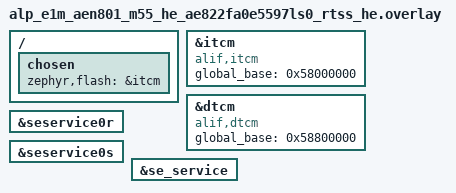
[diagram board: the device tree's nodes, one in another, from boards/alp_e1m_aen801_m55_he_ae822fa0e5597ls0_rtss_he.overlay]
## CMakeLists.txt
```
# SPDX-License-Identifier: Apache-2.0
#
# aen-dualcore-he-master -- the HE-master -> HP-peer direction of B1 Option B,
# self-contained (unlike aen-dualcore-master, which is symmetric and needs the
# separate aen-dualcore-probe app hand-paired in as the HP peer). Built TWICE:
# the HE board target is the master role (src/main.c calls
# alp_mproc_boot_core(ALP_CORE_M55_HP, ...) via the deferred-TOC path -- see
# README.md for why this direction can't use the plain 501 release path); the
# HP board target is the peer role (a passive SRAM0 beacon, like
# aen-dualcore-probe). One source file, role picked by CONFIG_SOC_*_RTSS_HP
# (a SoC-core fact, true on either SKU) at compile time, same pattern as
# every other aen-dualcore-* example.
cmake_minimum_required(VERSION 3.20)
find_package(Zephyr REQUIRED HINTS $ENV{ZEPHYR_BASE})
project(aen_dualcore_he_master LANGUAGES C)
target_sources(app PRIVATE src/main.c)
```

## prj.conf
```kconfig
# SPDX-License-Identifier: Apache-2.0
#
# Bench RAM-run config, shared by both the HE (master) and HP (peer) builds.
# Role-specific Kconfig (the SE boot backend, the deferred-TOC selection) lives
# in boards/<he-target>.conf -- Zephyr auto-merges a boards/<fully-qualified
# board>.conf into this file, HP gets none of it and stays a lean beacon-only
# image, same split aen-dualcore-doorbell/aen-dualcore-ipc use elsewhere.
#
# Like every other aen-dualcore-* example: both M55 cores are read through one
# SWD buffer (master-agnostic), and a single UART5 can't serve both cores, so
# this stays on the RAM console rather than the newer Alp-UART default.
CONFIG_RAM_CONSOLE=y
CONFIG_RAM_CONSOLE_BUFFER_SIZE=2048
CONFIG_UART_CONSOLE=n
CONFIG_CONSOLE=y
CONFIG_PRINTK=y

# Keep the image small + deterministic for a RAM-run. LOG MUST stay off --
# CONFIG_LOG=y reroutes printk into the logging subsystem, which has no
# RAM-console backend, so the RESULT line never reaches 'ram_console_buf'.
CONFIG_LOG=n

# Non-negotiable for this app, both boards: (1) the E8 D-cache maintenance
# loop hangs on this silicon (shared bench rule -- see aen-hp-core-smoke,
# aen-gpu2d-bench); (2) the two beacons this app polls (its own + the peer's)
# live in cross-core global SRAM0, which is NOT coherent between the M55-HE
# and M55-HP D-caches -- a cached read can sit on a stale line forever while
# the other core's write already landed, i.e. an all-else-correct build
# reports RESULT SKIP against a peer that is, in fact, up and heartbeating
# (PR #1080's finding on three sibling dual-core examples that omitted
# this). A cache-on variant would need sys_cache_data_flush_range on every
# beacon write + sys_cache_data_invd_range before every cross-core beacon
# read.
CONFIG_DCACHE=n
```

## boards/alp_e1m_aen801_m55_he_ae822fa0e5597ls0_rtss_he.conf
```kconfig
#
# E1M-AEN801 / Alif Ensemble E8: the MASTER role. HE is the SES-booted core
# here (ATOC entry ["load","boot"] @0x58000000); it releases the HP peer at
# runtime over the Secure Enclave boot service.
#
# Tier-2 driver Kconfigs (incl. CONFIG_ARM_MHUV2 / CONFIG_HAS_ALIF_SE_SERVICES)
# are gated under ALP_SDK.
CONFIG_ALP_SDK=y

# SE service transport. CONFIG_ARM_MHUV2 builds the in-tree "arm,mhuv2" IPM
# driver; CONFIG_HAS_ALIF_SE_SERVICES compiles the hal_alif SE client the
# SDK's boot backend consumes -- this app itself calls only the portable
# alp_mproc_boot_core() (<alp/mproc.h>).  Both default y under the relevant
# DT_HAS_*_ENABLED (boards/<this-file-minus-.conf>.overlay okays the SE
# mailbox nodes), set explicitly so the build is self-describing.
CONFIG_ARM_MHUV2=y
CONFIG_HAS_ALIF_SE_SERVICES=y

# The load-bearing selection: this build's peer is M55-HP, not M55-HE.
# Setting only THIS symbol is deliberate -- everything else cascades from its
# Kconfig defaults (zephyr/kconfigs/mproc-rpc-usb.kconfig):
#   - CONFIG_ALP_SDK_MPROC_BOOT_ALIF_SE_DEFERRED_TOC defaults to y once the
#     peer is HP (the plain service-501 release path is vendor-documented
#     broken for an HP peer -- see README.md and
#     src/backends/mproc/alif_se_boot.c); it stays n for an HE peer, where
#     501 is bench-proven fine and flipping the default would break every
#     existing HE-peer ATOC.
#   - CONFIG_ALP_SDK_MPROC_BOOT_ALIF_SE_DEFERRED_TOC_ENTRY_ID defaults to
#     "ALP-HP" once the peer is HP -- the ATOC entry key
#     se_service_process_toc_entry() un-defers at runtime (see README.md's
#     ATOC shape: this string MUST match the flashed entry's JSON key
#     exactly, or the un-defer request silently targets nothing).
# Hardcoding either of those here instead would fight the single-source
# Kconfig default and drift if the defaults ever change.
CONFIG_ALP_SDK_MPROC_BOOT_ALIF_SE_DEFERRED_TOC_PEER_IS_HP=y
```

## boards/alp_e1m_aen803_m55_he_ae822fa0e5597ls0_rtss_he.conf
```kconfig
#
# E1M-AEN803 / Alif Ensemble E8: the MASTER role. HE is the SES-booted core
# here (ATOC entry ["load","boot"] @0x58000000); it releases the HP peer at
# runtime over the Secure Enclave boot service.
#
# Tier-2 driver Kconfigs (incl. CONFIG_ARM_MHUV2 / CONFIG_HAS_ALIF_SE_SERVICES)
# are gated under ALP_SDK.
CONFIG_ALP_SDK=y

# SE service transport. CONFIG_ARM_MHUV2 builds the in-tree "arm,mhuv2" IPM
# driver; CONFIG_HAS_ALIF_SE_SERVICES compiles the hal_alif SE client the
# SDK's boot backend consumes -- this app itself calls only the portable
# alp_mproc_boot_core() (<alp/mproc.h>).  Both default y under the relevant
# DT_HAS_*_ENABLED (boards/<this-file-minus-.conf>.overlay okays the SE
# mailbox nodes), set explicitly so the build is self-describing.
CONFIG_ARM_MHUV2=y
CONFIG_HAS_ALIF_SE_SERVICES=y

# The load-bearing selection: this build's peer is M55-HP, not M55-HE.
# Setting only THIS symbol is deliberate -- everything else cascades from its
# Kconfig defaults (zephyr/kconfigs/mproc-rpc-usb.kconfig):
#   - CONFIG_ALP_SDK_MPROC_BOOT_ALIF_SE_DEFERRED_TOC defaults to y once the
#     peer is HP (the plain service-501 release path is vendor-documented
#     broken for an HP peer -- see README.md and
#     src/backends/mproc/alif_se_boot.c); it stays n for an HE peer, where
#     501 is bench-proven fine and flipping the default would break every
#     existing HE-peer ATOC.
#   - CONFIG_ALP_SDK_MPROC_BOOT_ALIF_SE_DEFERRED_TOC_ENTRY_ID defaults to
#     "ALP-HP" once the peer is HP -- the ATOC entry key
#     se_service_process_toc_entry() un-defers at runtime (see README.md's
#     ATOC shape: this string MUST match the flashed entry's JSON key
#     exactly, or the un-defer request silently targets nothing).
# Hardcoding either of those here instead would fight the single-source
# Kconfig default and drift if the defaults ever change.
CONFIG_ALP_SDK_MPROC_BOOT_ALIF_SE_DEFERRED_TOC_PEER_IS_HP=y
```

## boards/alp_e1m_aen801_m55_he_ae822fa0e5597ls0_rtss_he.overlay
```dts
/*
 * Copyright (c) 2026 Alp Lab AB
 * SPDX-License-Identifier: Apache-2.0
 *
 * aen-dualcore-he-master overlay for the E1M-AEN801 (Ensemble E8, M55-HE)
 * MASTER role RAM-run.
 *
 * The SE SERVICE transport nodes live in the E8 SoC overlay
 * (zephyr/dts/alif/ensemble_e8_peripherals.dtsi) status="disabled" by default
 * (they are SoC-fixed: the RTSS-HE <-> SE MHUv2 mailbox pair + the se_service
 * root node). This overlay enables them for the RTSS-HE core:
 *   - seservice0r (arm,mhuv2 @ 0x40040000, IRQ 37, "rx") -- SE -> RTSS inbound
 *   - seservice0s (arm,mhuv2 @ 0x40050000, IRQ 38, "tx") -- RTSS -> SE outbound
 *   - se_service  (alif,secure-enclave-services) -- ties the two via phandles
 * No clocks / pinctrl: the MHUv2 mailboxes are core-internal (no pads, no
 * peripheral clock gate); the driver only maps MMIO + wires the IRQ.
 */

/*
 * RAM-run: retarget ROM to ITCM (path-reference form &itcm; the phandle-array
 * form makes FLASH_SIZE=0 and overflows the link) -- the aen-adc-regcheck
 * precedent, same as every other aen-dualcore-* example.
 */
/ {
	chosen {
		zephyr,flash = &itcm;
		/delete-property/ zephyr,code-partition;
	};
};

/*
 * itcm/dtcm `global_base` for local_to_global() -- hal_alif se_service.c puts
 * its outbound SE message buffer through local_to_global() (soc_memory_map.h),
 * which reads DT_PROP(itcm/dtcm, global_base) to translate the M55-local
 * address into the global view the SE's DMA sees. Upstream Zephyr's
 * arm,itcm/arm,dtcm bindings have no such prop, so re-`compatible` the nodes
 * onto the alp-sdk alif,itcm/alif,dtcm bindings (which declare global_base)
 * and set the E8 RTSS-HE global TCM aliases (ITCM 0x58000000, DTCM
 * 0x58800000), the same values every other SE-service-using aen-dualcore-*
 * HE build sets. The HP peer role in this same example needs none of this --
 * it never calls into se_service.c, so its overlay skips both the SE nodes
 * and this re-`compatible`.
 */
&itcm {
	compatible = "alif,itcm";
	global_base = <0x58000000>;
};

&dtcm {
	compatible = "alif,dtcm";
	global_base = <0x58800000>;
};

&seservice0r {
	status = "okay";
};

&seservice0s {
	status = "okay";
};

&se_service {
	status = "okay";
};
```

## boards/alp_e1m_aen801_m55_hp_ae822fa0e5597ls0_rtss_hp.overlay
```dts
/*
 * Copyright (c) 2026 Alp Lab AB
 * SPDX-License-Identifier: Apache-2.0
 *
 * aen-dualcore-he-master overlay for the E1M-AEN801 (Ensemble E8, M55-HP)
 * PEER role RAM-run.
 *
 * The peer role never calls alp_mproc_boot_core() or any other SE service --
 * it only stamps a beacon in global SRAM0 (see src/main.c) -- so unlike the HE
 * master's overlay, no SE mailbox nodes and no itcm/dtcm global_base
 * re-`compatible` are needed here (local_to_global() is never reached on this
 * side). Just the ITCM link retarget, the same one aen-dualcore-probe uses for
 * both boards via a single app.overlay.
 */
/ {
	chosen {
		zephyr,flash = &itcm;
		/delete-property/ zephyr,code-partition;
	};
};
```

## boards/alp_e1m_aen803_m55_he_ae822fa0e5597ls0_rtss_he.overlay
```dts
/*
 * Copyright (c) 2026 Alp Lab AB
 * SPDX-License-Identifier: Apache-2.0
 *
 * aen-dualcore-he-master overlay for the E1M-AEN803 (Ensemble E8, M55-HE)
 * MASTER role RAM-run.
 *
 * The SE SERVICE transport nodes live in the E8 SoC overlay
 * (zephyr/dts/alif/ensemble_e8_peripherals.dtsi) status="disabled" by default
 * (they are SoC-fixed: the RTSS-HE <-> SE MHUv2 mailbox pair + the se_service
 * root node). This overlay enables them for the RTSS-HE core:
 *   - seservice0r (arm,mhuv2 @ 0x40040000, IRQ 37, "rx") -- SE -> RTSS inbound
 *   - seservice0s (arm,mhuv2 @ 0x40050000, IRQ 38, "tx") -- RTSS -> SE outbound
 *   - se_service  (alif,secure-enclave-services) -- ties the two via phandles
 * No clocks / pinctrl: the MHUv2 mailboxes are core-internal (no pads, no
 * peripheral clock gate); the driver only maps MMIO + wires the IRQ.
 */

/*
 * RAM-run: retarget ROM to ITCM (path-reference form &itcm; the phandle-array
 * form makes FLASH_SIZE=0 and overflows the link) -- the aen-adc-regcheck
 * precedent, same as every other aen-dualcore-* example.
 */
/ {
	chosen {
		zephyr,flash = &itcm;
		/delete-property/ zephyr,code-partition;
	};
};

/*
 * itcm/dtcm `global_base` for local_to_global() -- hal_alif se_service.c puts
 * its outbound SE message buffer through local_to_global() (soc_memory_map.h),
 * which reads DT_PROP(itcm/dtcm, global_base) to translate the M55-local
 * address into the global view the SE's DMA sees. Upstream Zephyr's
 * arm,itcm/arm,dtcm bindings have no such prop, so re-`compatible` the nodes
 * onto the alp-sdk alif,itcm/alif,dtcm bindings (which declare global_base)
 * and set the E8 RTSS-HE global TCM aliases (ITCM 0x58000000, DTCM
 * 0x58800000), the same values every other SE-service-using aen-dualcore-*
 * HE build sets. The HP peer role in this same example needs none of this --
 * it never calls into se_service.c, so its overlay skips both the SE nodes
 * and this re-`compatible`.
 */
&itcm {
	compatible = "alif,itcm";
	global_base = <0x58000000>;
};

&dtcm {
	compatible = "alif,dtcm";
	global_base = <0x58800000>;
};

&seservice0r {
	status = "okay";
};

&seservice0s {
	status = "okay";
};

&se_service {
	status = "okay";
};
```

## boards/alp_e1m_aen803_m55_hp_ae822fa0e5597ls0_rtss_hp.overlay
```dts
/*
 * Copyright (c) 2026 Alp Lab AB
 * SPDX-License-Identifier: Apache-2.0
 *
 * aen-dualcore-he-master overlay for the E1M-AEN803 (Ensemble E8, M55-HP)
 * PEER role RAM-run.
 *
 * The peer role never calls alp_mproc_boot_core() or any other SE service --
 * it only stamps a beacon in global SRAM0 (see src/main.c) -- so unlike the HE
 * master's overlay, no SE mailbox nodes and no itcm/dtcm global_base
 * re-`compatible` are needed here (local_to_global() is never reached on this
 * side). Just the ITCM link retarget, the same one aen-dualcore-probe uses for
 * both boards via a single app.overlay.
 */
/ {
	chosen {
		zephyr,flash = &itcm;
		/delete-property/ zephyr,code-partition;
	};
};
```

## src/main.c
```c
/*
 * Copyright (c) 2026 Alp Lab AB
 * SPDX-License-Identifier: Apache-2.0
 *
 * aen-dualcore-he-master -- the HE-master -> HP-peer direction of B1 Option B
 * (portable alp_mproc_boot_core(), <alp/mproc.h>), as its OWN example instead
 * of a hand-paired combination of two others.
 *
 * Every other AEN dual-core example that releases a peer (aen-dualcore-master,
 * aen-dualcore-doorbell, aen-dualcore-ipc, ...) releases it HP-master ->
 * HE-peer. That direction works with the plain se_service_boot_cpu() release
 * path (service 501). This example is the OTHER direction -- HE releases HP
 * -- which 501 cannot do at all: Alif's SE Host Services API docs
 * (SE_Host_Services_API_v1.109.0.pdf) say plainly that 501 "does not perform
 * image loading, verification, etc., it just boots the core" (p.112), and
 * that resetting the M55-HP core specifically invalidates its TCM content
 * on release -- p.112 scopes this to "FUSION REV_Bx devices", p.115 instead
 * says "Ensemble devices" with no qualifier
 * (E8 is Ensemble, so p.115 covers it either way; the two vendor passages
 * disagree with each other on scope and are cited here rather than
 * resolved). Bench-measured on E8 (2026-07-31, HE master releasing an HP
 * peer via 501): the SES table reported HP Loaded/Verified, but its ITCM
 * read as uninitialized SRAM, and releasing it vectored the core from empty
 * memory -- CFSR=0x00000101 (IACCVIOL+IBUSERR), PC=0xEFFFFFFE.
 *
 * The fix is service 500 (se_service_process_toc_entry(), "a convenient way
 * to boot a CPU core", p.112) against a peer ATOC entry flagged
 * ["load","boot","deferred"]: the SES skips the entry entirely at power-on
 * (SETOOLS guide AUGD0005 v1.110.0 p.35: "skipped at boot time, i.e., no boot OR
 * load"), and this master's boot_core() call un-defers it at runtime -- load,
 * verify AND release together, strictly AFTER whatever reset the release
 * involves, matching p.115's own documented remedy (reset -> reload ->
 * release). This build selects that path via
 * CONFIG_ALP_SDK_MPROC_BOOT_ALIF_SE_DEFERRED_TOC_PEER_IS_HP=y
 * (boards/alp_e1m_aen801_m55_he_ae822fa0e5597ls0_rtss_he.conf), which
 * cascades CONFIG_ALP_SDK_MPROC_BOOT_ALIF_SE_DEFERRED_TOC=y and
 * CONFIG_..._ENTRY_ID="ALP-HP" from their own Kconfig defaults -- see
 * zephyr/kconfigs/mproc-rpc-usb.kconfig. Silicon-proven on E8, 2026-08-01,
 * as this exact self-contained example (a from-scratch bench rebuild
 * reproduced the authoring build's zephyr.bin md5s bit-exactly): see
 * README.md.
 *
 * ONE app, role-by-board, same pattern as every sibling:
 *   - built for the RTSS-HE board -> MASTER: SES-booted normally
 *     (["load","boot"] @0x58000000), calls alp_mproc_boot_core() to release
 *     the deferred HP peer.
 *   - built for the RTSS-HP board -> PEER: SES-DEFERRED (["load","boot",
 *     "deferred"] @0x50000000), never boots itself and never calls a boot
 *     API -- it only comes up when the master's runtime request un-defers
 *     it, then stamps a global-SRAM0 beacon like every other peer role in
 *     this family.
 *
 * alp_mproc_boot_core() returning ALP_OK only confirms the SE boot authority
 * ACCEPTED the un-defer request -- it says nothing about whether the peer
 * actually came up (that is the entire lesson this example exists to teach:
 * the plain-501 direction above is ALSO accepted with rc=ALP_OK and STILL
 * fails on real silicon). So this master polls the peer's own beacon for a
 * bounded window and only claims PASS once that word is observed to move --
 * never on the accepted return code alone.
 *
 * Message discipline: every non-PASS verdict below states what was
 * OBSERVED (the peer's beacon word did not advance within the bound), never
 * an inferred cause ("peer never ran") -- CONFIG_DCACHE=n exists specifically
 * because an inferred "peer never ran" was WRONG on this bench: the peer was
 * running and its beacon was genuinely advancing, just invisible to a cached
 * cross-core read (see prj.conf).
 *
 * Build (see README.md for the ATOC + flags this pairs with):
 *   west build -b alp_e1m_aen801_m55_he/ae822fa0e5597ls0/rtss_he \
 *     examples/aen/aen-dualcore-he-master -d build/he -- \
 *     "-DEXTRA_ZEPHYR_MODULES=<alp-sdk>;<hal_alif>"
 *   west build -b alp_e1m_aen801_m55_hp/ae822fa0e5597ls0/rtss_hp \
 *     examples/aen/aen-dualcore-he-master -d build/hp -- \
 *     "-DEXTRA_ZEPHYR_MODULES=<alp-sdk>;<hal_alif>"
 */

#include <stdbool.h>
#include <stdint.h>
#include <zephyr/kernel.h>
#include <zephyr/sys/printk.h>

/* <alp/mproc.h> is included further down, MASTER-role only: the PEER role
 * never calls into the SDK (it doesn't even build with CONFIG_ALP_SDK=y --
 * see prj.conf / boards/ *.conf), so its include path doesn't carry this
 * header at all. Keeping the include role-scoped, not just the call, keeps
 * the peer build exactly as lean as aen-dualcore-probe's. */

/* Global-SRAM0 beacon addresses + magics -- the same scheme (and the same
 * literal addresses) every aen-dualcore-* example uses, so a bench operator
 * reading this app over SWD needs no new mental model. 0x02000000 itself
 * reads back 0 even when running (reserved/special per the bench), so both
 * beacons sit at nonzero offsets. */
#define HP_BEACON ((volatile uint32_t *)0x02000010U) /* HP's own beacon slot */
#define HP_MAGIC  0xB1B10090U
#define HE_BEACON ((volatile uint32_t *)0x02001010U) /* HE's own beacon slot */
#define HE_BOOT   ((volatile uint32_t *)0x02001018U) /* HE-only: boot_core() rc */
#define HE_MAGIC  0xB1B100E0U
#define HP_ENTRY  0x50000000U /* HP ITCM global alias = the deferred ATOC entry's loadAddress */

/* Bounded wait for the peer's heartbeat to move at least once. Generous vs.
 * a cold M55 boot-to-main(): if the peer never advances within this window
 * on a bench where boot_core reported success, that IS the observation --
 * not proof of what the peer is doing, just that this core never saw it
 * move. */
#define PEER_HB_TIMEOUT_MS 2000U
#define PEER_HB_POLL_MS    20U

#if defined(CONFIG_SOC_AE822FA0E5597LS0_RTSS_HP)

/* PEER role: passive. This core's ATOC entry is ["load","boot","deferred"],
 * so it never runs until the HE master's boot_core() call un-defers it --
 * reaching main() at all is itself part of the proof the deferred-TOC
 * release worked. From here it behaves exactly like aen-dualcore-probe:
 * stamp a beacon, then heartbeat forever for the master (or a bench SWD
 * read) to observe.
 */
int main(void)
{
	printk("\n=== aen-dualcore-he-master (HP peer) beacon@0x02000010 ===\n");

	HP_BEACON[0] = HP_MAGIC;
	HP_BEACON[1] = 0U;

	for (uint32_t hb = 1U;; hb++) {
		HP_BEACON[1] = hb;
		if ((hb & 0x3FFU) == 0U) {
			printk("HP heartbeat %u\n", hb);
		}
		for (volatile uint32_t d = 0U; d < 200000U; d++) {
			/* crude delay so the heartbeat is human-observable */
		}
	}

	return 0;
}

#else

#include <alp/mproc.h>

/* MASTER role (default: any board that isn't the HP peer, i.e. RTSS-HE --
 * core-role selection, not a peripheral-presence gate, same convention as
 * every sibling example). */
int main(void)
{
	printk("\n=== aen-dualcore-he-master (HE master) -- release the deferred HP peer "
	       "via alp_mproc_boot_core ===\n");

	HE_BEACON[0] = HE_MAGIC;
	HE_BEACON[1] = 0U;

	alp_status_t rc = alp_mproc_boot_core(ALP_CORE_M55_HP, HP_ENTRY);

	HE_BOOT[0] = 0xB007C0DEU;
	HE_BOOT[1] = (uint32_t)rc;
	printk("alp_mproc_boot_core(M55-HP, 0x%08x) rc=%d\n", HP_ENTRY, (int)rc);

	if (rc != ALP_OK) {
		/* State only the observation: boot_core() itself returned a
		 * nonzero rc. Do NOT name "this build's PEER_IS_HP not matching
		 * the flashed ATOC" as the cause -- the backend's peer-mismatch
		 * guard (alif_se_boot.c) compares this CALL's core argument
		 * (hardcoded ALP_CORE_M55_HP above) against the CONFIGURED peer,
		 * never the flashed ATOC, and on this exact build a PEER_IS_HP=n
		 * misconfiguration does NOT reach that guard at all: it makes
		 * CONFIG_..._DEFERRED_TOC default off too, so boot_core() falls
		 * through to the plain service-501 path and returns rc=0 (a
		 * RESULT SKIP below, never this FAIL). A nonzero rc here is a
		 * real SE-backend/IO error. */
		printk("RESULT FAIL: alp_mproc_boot_core rc=%d\n", (int)rc);
	} else {
		/* Accepted is not proof: the plain-501 direction this example
		 * exists to correct ALSO returns ALP_OK and then the peer never
		 * comes up. The only evidence that counts is the peer's own
		 * beacon moving. */
		uint32_t peer_hb0   = HP_BEACON[1];
		bool     peer_alive = false;

		for (uint32_t t = 0U; t < PEER_HB_TIMEOUT_MS / PEER_HB_POLL_MS; t++) {
			k_msleep(PEER_HB_POLL_MS);
			if (HP_BEACON[0] == HP_MAGIC && HP_BEACON[1] != peer_hb0) {
				peer_alive = true;
				break;
			}
		}

		if (peer_alive) {
			printk("RESULT PASS: dualcore-he-master -- M55-HP booted and heartbeating "
			       "(peer beacon magic=0x%08x)\n",
			       HP_MAGIC);
		} else {
			/* Observation only: the beacon word did not move within the
			 * bound. Do NOT claim "the peer never ran" -- CONFIG_DCACHE=n
			 * in prj.conf exists precisely because that inferred claim was
			 * measured wrong on this bench (see prj.conf's comment). */
			printk("RESULT SKIP: dualcore-he-master -- alp_mproc_boot_core(M55-HP) "
			       "accepted (rc=0) but its beacon (0x02000010) did not advance "
			       "within %u ms\n",
			       PEER_HB_TIMEOUT_MS);
		}
	}

	for (uint32_t hb = 1U;; hb++) {
		HE_BEACON[1] = hb;
		for (volatile uint32_t d = 0U; d < 200000U; d++) {
		}
	}
	return 0;
}

#endif
```
